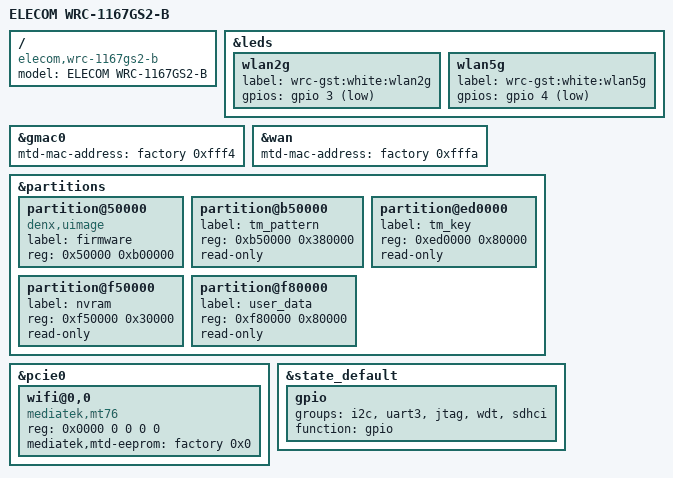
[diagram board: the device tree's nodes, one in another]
// SPDX-License-Identifier: GPL-2.0-or-later OR MIT
/dts-v1/;

#include "mt7621_elecom_wrc-gst.dtsi"

/ {
	compatible = "elecom,wrc-1167gs2-b", "mediatek,mt7621-soc";
	model = "ELECOM WRC-1167GS2-B";
};

&leds {
	wlan2g {
		label = "wrc-gst:white:wlan2g";
		gpios = <&gpio 3 GPIO_ACTIVE_LOW>;
	};

	wlan5g {
		label = "wrc-gst:white:wlan5g";
		gpios = <&gpio 4 GPIO_ACTIVE_LOW>;
	};
};

&gmac0 {
	mtd-mac-address = <&factory 0xfff4>;
};

&wan {
	mtd-mac-address = <&factory 0xfffa>;
};

&partitions {
	partition@50000 {
		compatible = "denx,uimage";
		label = "firmware";
		reg = <0x50000 0xb00000>;
	};

	partition@b50000 {
		label = "tm_pattern";
		reg = <0xb50000 0x380000>;
		read-only;
	};

	partition@ed0000 {
		label = "tm_key";
		reg = <0xed0000 0x80000>;
		read-only;
	};

	partition@f50000 {
		label = "nvram";
		reg = <0xf50000 0x30000>;
		read-only;
	};

	partition@f80000 {
		label = "user_data";
		reg = <0xf80000 0x80000>;
		read-only;
	};
};

&pcie0 {
	wifi@0,0 {
		compatible = "mediatek,mt76";
		reg = <0x0000 0 0 0 0>;
		mediatek,mtd-eeprom = <&factory 0x0>;
	};
};

&state_default {
	gpio {
		groups = "i2c", "uart3", "jtag", "wdt", "sdhci";
		function = "gpio";
	};
};
